# mc200 register map
Registers are 32-bit, access not given, no defined reset value unless marked. A register's access mark holds for its fields unless they carry their own. Addresses are absolute; registers are grouped by the start of their names; [hi:lo] are bit positions.

## QSPI0
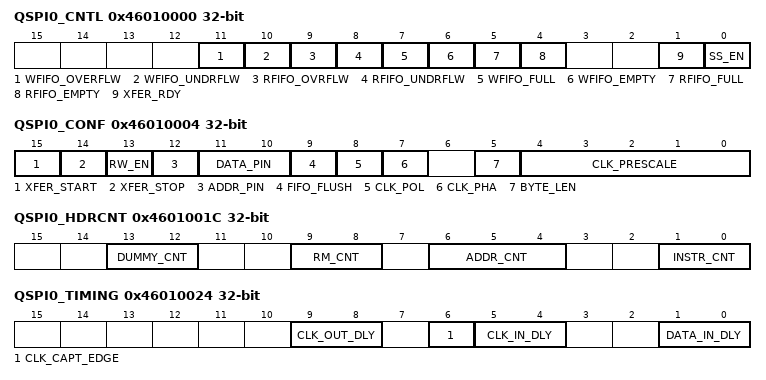
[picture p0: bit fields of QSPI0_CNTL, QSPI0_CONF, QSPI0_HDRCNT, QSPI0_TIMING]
0x46010000 QSPI0_CNTL
  [11] WFIFO_OVERFLW, [10] WFIFO_UNDRFLW, [9] RFIFO_OVRFLW, [8] RFIFO_UNDRFLW, [7] WFIFO_FULL, [6] WFIFO_EMPTY, [5] RFIFO_FULL, [4] RFIFO_EMPTY, [1] XFER_RDY, [0] SS_EN
0x46010004 QSPI0_CONF
  [15] XFER_START, [14] XFER_STOP, [13] RW_EN, [12] ADDR_PIN, [11:10] DATA_PIN, [9] FIFO_FLUSH, [8] CLK_POL, [7] CLK_PHA, [5] BYTE_LEN, [4:0] CLK_PRESCALE
0x46010008 QSPI0_DOUT
  [31:0] DATA_OUT
0x4601000C QSPI0_DIN
  [31:0] DATA_IN
0x46010010 QSPI0_INSTR
  [15:0] INSTR
0x46010014 QSPI0_ADDR
0x46010018 QSPI0_RDMODE
  [15:0] RMODE
0x4601001C QSPI0_HDRCNT
  [13:12] DUMMY_CNT, [9:8] RM_CNT, [6:4] ADDR_CNT, [1:0] INSTR_CNT
0x46010020 QSPI0_DINCNT
  [19:0] DATA_IN_CNT
0x46010024 QSPI0_TIMING
  [9:8] CLK_OUT_DLY, [6] CLK_CAPT_EDGE, [5:4] CLK_IN_DLY, [1:0] DATA_IN_DLY
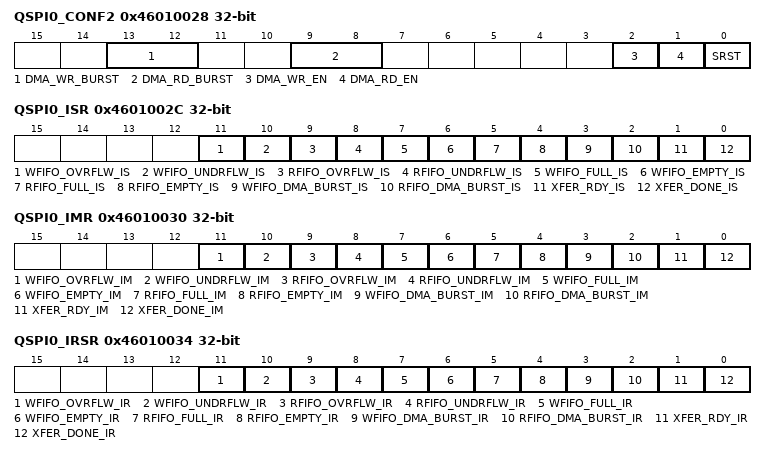
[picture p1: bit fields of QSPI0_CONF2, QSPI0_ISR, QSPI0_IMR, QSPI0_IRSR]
0x46010028 QSPI0_CONF2
  [13:12] DMA_WR_BURST, [9:8] DMA_RD_BURST, [2] DMA_WR_EN, [1] DMA_RD_EN, [0] SRST
0x4601002C QSPI0_ISR
  [11] WFIFO_OVRFLW_IS, [10] WFIFO_UNDRFLW_IS, [9] RFIFO_OVRFLW_IS, [8] RFIFO_UNDRFLW_IS, [7] WFIFO_FULL_IS, [6] WFIFO_EMPTY_IS, [5] RFIFO_FULL_IS, [4] RFIFO_EMPTY_IS, [3] WFIFO_DMA_BURST_IS, [2] RFIFO_DMA_BURST_IS, [1] XFER_RDY_IS, [0] XFER_DONE_IS
0x46010030 QSPI0_IMR
  [11] WFIFO_OVRFLW_IM, [10] WFIFO_UNDRFLW_IM, [9] RFIFO_OVRFLW_IM, [8] RFIFO_UNDRFLW_IM, [7] WFIFO_FULL_IM, [6] WFIFO_EMPTY_IM, [5] RFIFO_FULL_IM, [4] RFIFO_EMPTY_IM, [3] WFIFO_DMA_BURST_IM, [2] RFIFO_DMA_BURST_IM, [1] XFER_RDY_IM, [0] XFER_DONE_IM
0x46010034 QSPI0_IRSR
  [11] WFIFO_OVRFLW_IR, [10] WFIFO_UNDRFLW_IR, [9] RFIFO_OVRFLW_IR, [8] RFIFO_UNDRFLW_IR, [7] WFIFO_FULL_IR, [6] WFIFO_EMPTY_IR, [5] RFIFO_FULL_IR, [4] RFIFO_EMPTY_IR, [3] WFIFO_DMA_BURST_IR, [2] RFIFO_DMA_BURST_IR, [1] XFER_RDY_IR, [0] XFER_DONE_IR
0x46010038 QSPI0_ISC
  [0] XFER_DONE_IC

## SSP0
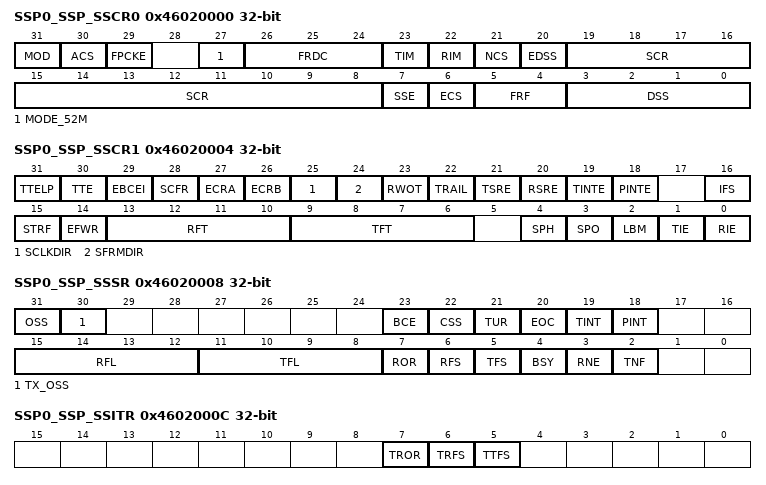
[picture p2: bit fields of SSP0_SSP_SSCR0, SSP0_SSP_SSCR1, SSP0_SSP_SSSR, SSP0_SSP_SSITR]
0x46020000 SSP0_SSP_SSCR0
  [31] MOD, [30] ACS, [29] FPCKE, [27] MODE_52M, [26:24] FRDC, [23] TIM, [22] RIM, [21] NCS, [20] EDSS, [19:8] SCR, [7] SSE, [6] ECS, [5:4] FRF, [3:0] DSS
0x46020004 SSP0_SSP_SSCR1
  [31] TTELP, [30] TTE, [29] EBCEI, [28] SCFR, [27] ECRA, [26] ECRB, [25] SCLKDIR, [24] SFRMDIR, [23] RWOT, [22] TRAIL, [21] TSRE, [20] RSRE, [19] TINTE, [18] PINTE, [16] IFS, [15] STRF, [14] EFWR, [13:10] RFT, [9:6] TFT, [4] SPH, [3] SPO, [2] LBM, [1] TIE, [0] RIE
0x46020008 SSP0_SSP_SSSR
  [31] OSS, [30] TX_OSS, [23] BCE, [22] CSS, [21] TUR, [20] EOC, [19] TINT, [18] PINT, [15:12] RFL, [11:8] TFL, [7] ROR, [6] RFS, [5] TFS, [4] BSY, [3] RNE, [2] TNF
0x4602000C SSP0_SSP_SSITR
  [7] TROR, [6] TRFS, [5] TTFS
0x46020010 SSP0_SSP_SSDR
  [31:0] DATA
0x46020028 SSP0_SSP_SSTO
  [23:0] TIMEOUT
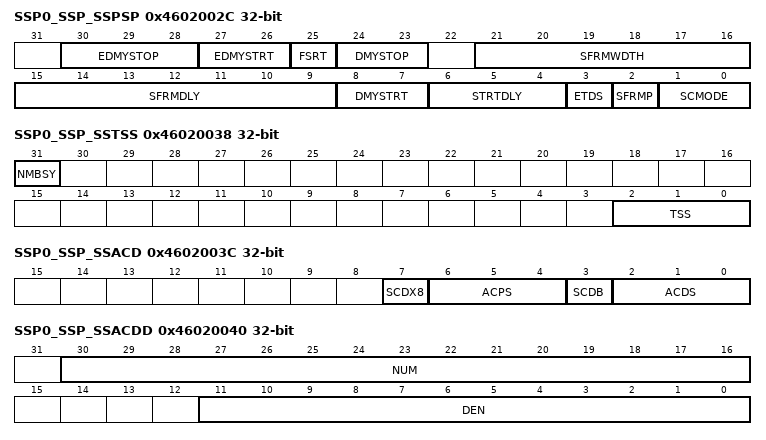
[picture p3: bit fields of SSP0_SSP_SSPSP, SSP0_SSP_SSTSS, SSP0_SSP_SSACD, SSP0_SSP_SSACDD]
0x4602002C SSP0_SSP_SSPSP
  [30:28] EDMYSTOP, [27:26] EDMYSTRT, [25] FSRT, [24:23] DMYSTOP, [21:16] SFRMWDTH, [15:9] SFRMDLY, [8:7] DMYSTRT, [6:4] STRTDLY, [3] ETDS, [2] SFRMP, [1:0] SCMODE
0x46020030 SSP0_SSP_SSTSA
  [7:0] TTSA
0x46020034 SSP0_SSP_SSRSA
  [7:0] RTSA
0x46020038 SSP0_SSP_SSTSS
  [31] NMBSY, [2:0] TSS
0x4602003C SSP0_SSP_SSACD
  [7] SCDX8, [6:4] ACPS, [3] SCDB, [2:0] ACDS
0x46020040 SSP0_SSP_SSACDD
  [30:16] NUM, [11:0] DEN

## SSP1
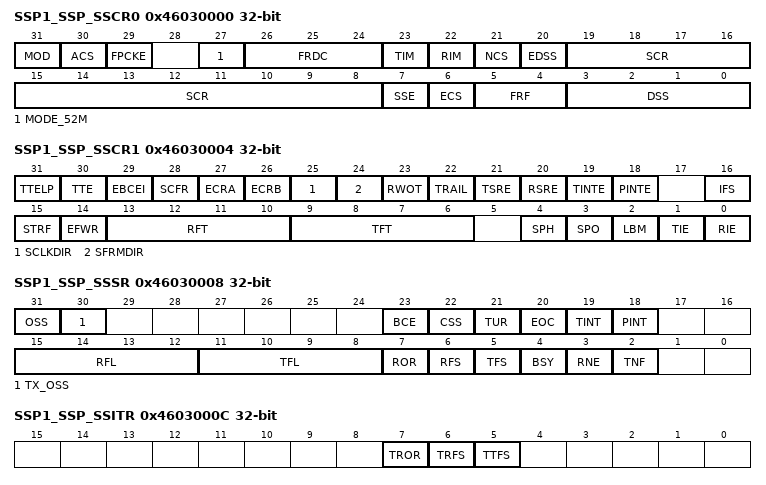
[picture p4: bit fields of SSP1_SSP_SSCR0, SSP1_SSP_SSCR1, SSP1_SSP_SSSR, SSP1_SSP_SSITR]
0x46030000 SSP1_SSP_SSCR0
  [31] MOD, [30] ACS, [29] FPCKE, [27] MODE_52M, [26:24] FRDC, [23] TIM, [22] RIM, [21] NCS, [20] EDSS, [19:8] SCR, [7] SSE, [6] ECS, [5:4] FRF, [3:0] DSS
0x46030004 SSP1_SSP_SSCR1
  [31] TTELP, [30] TTE, [29] EBCEI, [28] SCFR, [27] ECRA, [26] ECRB, [25] SCLKDIR, [24] SFRMDIR, [23] RWOT, [22] TRAIL, [21] TSRE, [20] RSRE, [19] TINTE, [18] PINTE, [16] IFS, [15] STRF, [14] EFWR, [13:10] RFT, [9:6] TFT, [4] SPH, [3] SPO, [2] LBM, [1] TIE, [0] RIE
0x46030008 SSP1_SSP_SSSR
  [31] OSS, [30] TX_OSS, [23] BCE, [22] CSS, [21] TUR, [20] EOC, [19] TINT, [18] PINT, [15:12] RFL, [11:8] TFL, [7] ROR, [6] RFS, [5] TFS, [4] BSY, [3] RNE, [2] TNF
0x4603000C SSP1_SSP_SSITR
  [7] TROR, [6] TRFS, [5] TTFS
0x46030010 SSP1_SSP_SSDR
  [31:0] DATA
0x46030028 SSP1_SSP_SSTO
  [23:0] TIMEOUT
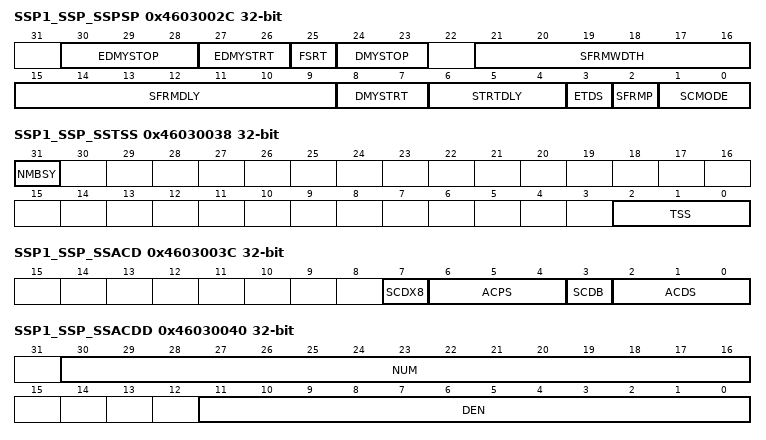
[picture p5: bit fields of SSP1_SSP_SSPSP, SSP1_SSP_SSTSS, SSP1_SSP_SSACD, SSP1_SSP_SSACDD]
0x4603002C SSP1_SSP_SSPSP
  [30:28] EDMYSTOP, [27:26] EDMYSTRT, [25] FSRT, [24:23] DMYSTOP, [21:16] SFRMWDTH, [15:9] SFRMDLY, [8:7] DMYSTRT, [6:4] STRTDLY, [3] ETDS, [2] SFRMP, [1:0] SCMODE
0x46030030 SSP1_SSP_SSTSA
  [7:0] TTSA
0x46030034 SSP1_SSP_SSRSA
  [7:0] RTSA
0x46030038 SSP1_SSP_SSTSS
  [31] NMBSY, [2:0] TSS
0x4603003C SSP1_SSP_SSACD
  [7] SCDX8, [6:4] ACPS, [3] SCDB, [2:0] ACDS
0x46030040 SSP1_SSP_SSACDD
  [30:16] NUM, [11:0] DEN
